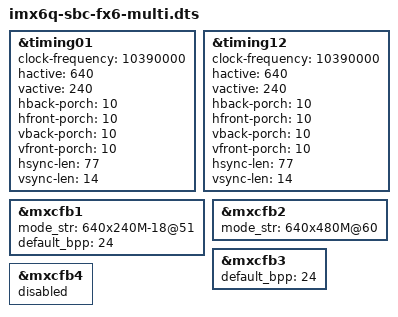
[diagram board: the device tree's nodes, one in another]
#include "imx6q-sbc-fx6.dts"
#include "imx6q-display-settings.dtsi"

/* lvds 1-st port timing */
&timing01 {
	clock-frequency = <10390000>;
        hactive = <640>;
        vactive = <240>;
        hback-porch = <10>;
        hfront-porch = <10>;
        vback-porch = <10>;
        vfront-porch = <10>;
        hsync-len = <77>;
        vsync-len = <14>;
};

/* lvds 2-nd port timing */
&timing12 {
	clock-frequency = <10390000>;
        hactive = <640>;
        vactive = <240>;
        hback-porch = <10>;
        hfront-porch = <10>;
        vback-porch = <10>;
        vfront-porch = <10>;
        hsync-len = <77>;
        vsync-len = <14>;
};

&mxcfb1 {
	/* lcd paralle output */
	LCD
	mode_str ="640x240M-18@51";
	default_bpp = <24>;
	status = "okay";
};

&mxcfb2 {
	/* hdmi */
	HDMI
	mode_str ="640x480M@60";
	status = "okay";
};

&mxcfb3 {
	/* ldb */
	LDB
	default_bpp = <24>;
	status = "okay";
};

&mxcfb4 {
	status = "disabled";
};

